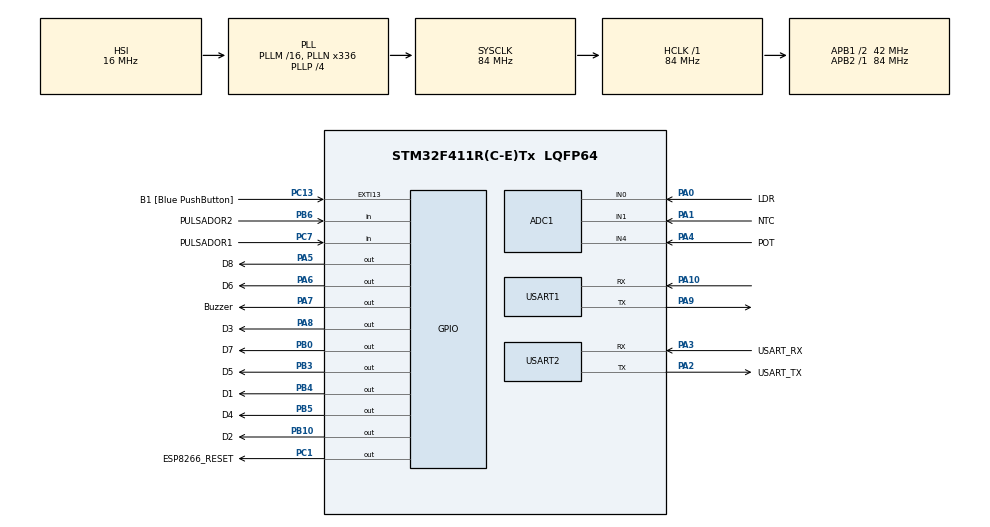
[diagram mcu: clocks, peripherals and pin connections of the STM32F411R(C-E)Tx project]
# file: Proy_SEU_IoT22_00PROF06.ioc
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ADC1.Channel-0\#ChannelRegularConversion=ADC_CHANNEL_0
ADC1.NbrOfConversionFlag=1
ADC1.Rank-0\#ChannelRegularConversion=1
ADC1.SamplingTime-0\#ChannelRegularConversion=ADC_SAMPLETIME_3CYCLES
ADC1.master=1
Dma.Request0=USART1_RX
Dma.Request1=USART2_RX
Dma.Request2=USART1_TX
Dma.USART1_RX.0.Direction=DMA_PERIPH_TO_MEMORY
Dma.USART1_RX.0.FIFOMode=DMA_FIFOMODE_DISABLE
Dma.USART1_RX.0.Instance=DMA2_Stream2
Dma.USART1_RX.0.MemDataAlignment=DMA_MDATAALIGN_BYTE
Dma.USART1_RX.0.MemInc=DMA_MINC_ENABLE
Dma.USART1_RX.0.Mode=DMA_NORMAL
Dma.USART1_RX.0.PeriphDataAlignment=DMA_PDATAALIGN_BYTE
Dma.USART1_RX.0.PeriphInc=DMA_PINC_DISABLE
Dma.USART1_RX.0.Priority=DMA_PRIORITY_LOW
Dma.USART1_TX.2.Direction=DMA_MEMORY_TO_PERIPH
Dma.USART1_TX.2.FIFOMode=DMA_FIFOMODE_DISABLE
Dma.USART1_TX.2.Instance=DMA2_Stream7
Dma.USART1_TX.2.MemDataAlignment=DMA_MDATAALIGN_BYTE
Dma.USART1_TX.2.MemInc=DMA_MINC_ENABLE
Dma.USART1_TX.2.Mode=DMA_NORMAL
Dma.USART1_TX.2.PeriphDataAlignment=DMA_PDATAALIGN_BYTE
Dma.USART1_TX.2.PeriphInc=DMA_PINC_DISABLE
Dma.USART1_TX.2.Priority=DMA_PRIORITY_LOW
Dma.USART2_RX.1.Direction=DMA_PERIPH_TO_MEMORY
Dma.USART2_RX.1.FIFOMode=DMA_FIFOMODE_DISABLE
Dma.USART2_RX.1.Instance=DMA1_Stream5
Dma.USART2_RX.1.MemDataAlignment=DMA_MDATAALIGN_BYTE
Dma.USART2_RX.1.MemInc=DMA_MINC_ENABLE
Dma.USART2_RX.1.Mode=DMA_NORMAL
Dma.USART2_RX.1.PeriphDataAlignment=DMA_PDATAALIGN_BYTE
Dma.USART2_RX.1.PeriphInc=DMA_PINC_DISABLE
Dma.USART2_RX.1.Priority=DMA_PRIORITY_LOW
FREERTOS.INCLUDE_vTaskDelayUntil=1
FREERTOS.Tasks01=defaultTask,24,128,StartDefaultTask,Default,NULL,Dynamic,NULL,NULL
FREERTOS.configENABLE_FPU=1
FREERTOS.configTOTAL_HEAP_SIZE=80000
FREERTOS.configUSE_NEWLIB_REENTRANT=1
Mcu.Family=STM32F4
Mcu.Name=STM32F411R(C-E)Tx
Mcu.Package=LQFP64
NVIC.DMA1_Stream5_IRQn=true\:5\:0\:false\:false\:true\:true\:true\:true\:true
NVIC.DMA2_Stream2_IRQn=true\:5\:0\:false\:false\:true\:true\:true\:true\:true
NVIC.DMA2_Stream7_IRQn=true\:5\:0\:false\:false\:true\:true\:true\:true\:true
NVIC.PriorityGroup=NVIC_PRIORITYGROUP_4
PA0-WKUP.GPIO_Label=LDR
PA0-WKUP.Signal=ADCx_IN0
PA1.GPIO_Label=NTC
PA1.Signal=ADCx_IN1
PA10.Mode=Asynchronous
PA10.Signal=USART1_RX
PA13.GPIO_Label=TMS
PA13.Mode=Serial_Wire
PA13.Signal=SYS_JTMS-SWDIO
PA14.GPIO_Label=TCK
PA14.Mode=Serial_Wire
PA14.Signal=SYS_JTCK-SWCLK
PA2.GPIO_Label=USART_TX
PA2.Mode=Asynchronous
PA2.Signal=USART2_TX
PA3.GPIO_Label=USART_RX
PA3.Mode=Asynchronous
PA3.Signal=USART2_RX
PA4.GPIO_Label=POT
PA4.Signal=ADCx_IN4
PA5.GPIO_Label=D8
PA5.Signal=GPIO_Output
PA6.GPIO_Label=D6
PA6.GPIO_Speed=GPIO_SPEED_FREQ_HIGH
PA6.PinState=GPIO_PIN_SET
PA6.Signal=GPIO_Output
PA7.GPIO_Label=Buzzer
PA7.Signal=GPIO_Output
PA8.GPIO_Label=D3
PA8.Signal=GPIO_Output
PA9.Mode=Asynchronous
PA9.Signal=USART1_TX
PB0.GPIO_Label=D7
PB0.Signal=GPIO_Output
PB10.GPIO_Label=D2
PB10.Signal=GPIO_Output
PB3.GPIO_Label=D5
PB3.Signal=GPIO_Output
PB4.GPIO_Label=D1
PB4.Signal=GPIO_Output
PB5.GPIO_Label=D4
PB5.Signal=GPIO_Output
PB6.GPIO_Label=PULSADOR2
PB6.GPIO_PuPd=GPIO_PULLUP
PB6.Signal=GPIO_Input
PC1.GPIO_Label=ESP8266_RESET
PC1.PinState=GPIO_PIN_RESET
PC1.Signal=GPIO_Output
PC13-ANTI_TAMP.GPIO_Label=B1 [Blue PushButton]
PC13-ANTI_TAMP.GPIO_ModeDefaultEXTI=GPIO_MODE_IT_FALLING
PC13-ANTI_TAMP.Signal=GPXTI13
PC14-OSC32_IN.Mode=LSE-External-Oscillator
PC14-OSC32_IN.Signal=RCC_OSC32_IN
PC15-OSC32_OUT.Mode=LSE-External-Oscillator
PC15-OSC32_OUT.Signal=RCC_OSC32_OUT
PC7.GPIO_Label=PULSADOR1
PC7.GPIO_PuPd=GPIO_PULLUP
PC7.Signal=GPIO_Input
PH0\ -\ OSC_IN.Mode=HSE-External-Clock-Source
PH0\ -\ OSC_IN.Signal=RCC_OSC_IN
PH1\ -\ OSC_OUT.Mode=HSE-External-Clock-Source
PH1\ -\ OSC_OUT.Signal=RCC_OSC_OUT
ProjectManager.HeapSize=0x200
ProjectManager.StackSize=0x400
ProjectManager.TargetToolchain=STM32CubeIDE
RCC.48MHZClocksFreq_Value=84000000
RCC.AHBFreq_Value=84000000
RCC.APB1CLKDivider=RCC_HCLK_DIV2
RCC.APB1Freq_Value=42000000
RCC.APB1TimFreq_Value=84000000
RCC.APB2Freq_Value=84000000
RCC.APB2TimFreq_Value=84000000
RCC.CortexFreq_Value=84000000
RCC.FLatency-AdvancedSettings=FLASH_LATENCY_2
RCC.HCLKFreq_Value=84000000
RCC.HSE_VALUE=8000000
RCC.HSI_VALUE=16000000
RCC.PLLN=336
RCC.PLLP=RCC_PLLP_DIV4
RCC.SYSCLKFreq_VALUE=84000000
RCC.SYSCLKSource=RCC_SYSCLKSOURCE_PLLCLK
RCC.VCOOutputFreq_Value=336000000
SH.ADCx_IN0.0=ADC1_IN0,IN0
SH.ADCx_IN1.0=ADC1_IN1,IN1
SH.ADCx_IN4.0=ADC1_IN4,IN4
USART1.VirtualMode=VM_ASYNC
USART2.VirtualMode=VM_ASYNC
VP_FREERTOS_VS_CMSIS_V2.Mode=CMSIS_V2
board=NUCLEO-F411RE

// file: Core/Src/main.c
/* USER CODE BEGIN Header */
/**
  ******************************************************************************
  * @file           : main.c
  * @brief          : Main program body
  ******************************************************************************
  * @attention
  *
  * <h2><center>&copy; Copyright (c) 2021 STMicroelectronics.
  * All rights reserved.</center></h2>
  *
  * This software component is licensed by ST under BSD 3-Clause license,
  * the "License"; You may not use this file except in compliance with the
  * License. You may obtain a copy of the License at:
  *                        opensource.org/licenses/BSD-3-Clause
  *
  ******************************************************************************
  */
/* USER CODE END Header */
#include "main.h"
#include "cmsis_os.h"

/* USER CODE BEGIN Includes */
#include "tareas.h"

/* USER CODE END Includes */

 ADC_HandleTypeDef hadc1;

UART_HandleTypeDef huart1;
UART_HandleTypeDef huart2;
DMA_HandleTypeDef hdma_usart1_rx;
DMA_HandleTypeDef hdma_usart1_tx;
DMA_HandleTypeDef hdma_usart2_rx;

/* Definitions for defaultTask */
osThreadId_t defaultTaskHandle;
const osThreadAttr_t defaultTask_attributes = {
  .name = "defaultTask",
  .stack_size = 128 * 4,
  .priority = (osPriority_t) osPriorityNormal,
};
/* USER CODE BEGIN PV */
DMA_HandleTypeDef hdma_usart2_rx2;
/* USER CODE END PV */

void SystemClock_Config(void);
static void MX_GPIO_Init(void);
static void MX_DMA_Init(void);
static void MX_USART2_UART_Init(void);
static void MX_USART1_UART_Init(void);
static void MX_ADC1_Init(void);
void StartDefaultTask(void *argument);

int main(void)
{

  /* MCU Configuration--------------------------------------------------------*/

  /* Reset of all peripherals, Initializes the Flash interface and the Systick. */
  HAL_Init();

  /* Configure the system clock */
  SystemClock_Config();

  /* Initialize all configured peripherals */
  MX_GPIO_Init();
  MX_DMA_Init();
  MX_USART2_UART_Init();
  MX_USART1_UART_Init();
  MX_ADC1_Init();

  /* Init scheduler */
  osKernelInitialize();

  /* Create the thread(s) */
  /* creation of defaultTask */
  defaultTaskHandle = osThreadNew(StartDefaultTask, NULL, &defaultTask_attributes);

  /* USER CODE BEGIN RTOS_THREADS */
  /* add threads, ... */
  ESP8266_CONFIGURACION_INICIAL();

  // seminario_sincronizacion();
  /* USER CODE END RTOS_THREADS */

  /* Start scheduler */
  osKernelStart();

  /* We should never get here as control is now taken by the scheduler */
  /* Infinite loop */
  while (1)
  {

  }
}

void SystemClock_Config(void)
{
  RCC_OscInitTypeDef RCC_OscInitStruct = {0};
  RCC_ClkInitTypeDef RCC_ClkInitStruct = {0};

  /** Configure the main internal regulator output voltage
  */
  __HAL_RCC_PWR_CLK_ENABLE();
  __HAL_PWR_VOLTAGESCALING_CONFIG(PWR_REGULATOR_VOLTAGE_SCALE1);

  /** Initializes the RCC Oscillators according to the specified parameters
  * in the RCC_OscInitTypeDef structure.
  */
  RCC_OscInitStruct.OscillatorType = RCC_OSCILLATORTYPE_HSI;
  RCC_OscInitStruct.HSIState = RCC_HSI_ON;
  RCC_OscInitStruct.HSICalibrationValue = RCC_HSICALIBRATION_DEFAULT;
  RCC_OscInitStruct.PLL.PLLState = RCC_PLL_ON;
  RCC_OscInitStruct.PLL.PLLSource = RCC_PLLSOURCE_HSI;
  RCC_OscInitStruct.PLL.PLLM = 16;
  RCC_OscInitStruct.PLL.PLLN = 336;
  RCC_OscInitStruct.PLL.PLLP = RCC_PLLP_DIV4;
  RCC_OscInitStruct.PLL.PLLQ = 4;
  if (HAL_RCC_OscConfig(&RCC_OscInitStruct) != HAL_OK)
  {
    Error_Handler();
  }

  /** Initializes the CPU, AHB and APB buses clocks
  */
  RCC_ClkInitStruct.ClockType = RCC_CLOCKTYPE_HCLK|RCC_CLOCKTYPE_SYSCLK
                              |RCC_CLOCKTYPE_PCLK1|RCC_CLOCKTYPE_PCLK2;
  RCC_ClkInitStruct.SYSCLKSource = RCC_SYSCLKSOURCE_PLLCLK;
  RCC_ClkInitStruct.AHBCLKDivider = RCC_SYSCLK_DIV1;
  RCC_ClkInitStruct.APB1CLKDivider = RCC_HCLK_DIV2;
  RCC_ClkInitStruct.APB2CLKDivider = RCC_HCLK_DIV1;

  if (HAL_RCC_ClockConfig(&RCC_ClkInitStruct, FLASH_LATENCY_2) != HAL_OK)
  {
    Error_Handler();
  }
}

static void MX_ADC1_Init(void)
{

  ADC_ChannelConfTypeDef sConfig = {0};

  /** Configure the global features of the ADC (Clock, Resolution, Data Alignment and number of conversion)
  */
  hadc1.Instance = ADC1;
  hadc1.Init.ClockPrescaler = ADC_CLOCK_SYNC_PCLK_DIV4;
  hadc1.Init.Resolution = ADC_RESOLUTION_12B;
  hadc1.Init.ScanConvMode = DISABLE;
  hadc1.Init.ContinuousConvMode = DISABLE;
  hadc1.Init.DiscontinuousConvMode = DISABLE;
  hadc1.Init.ExternalTrigConvEdge = ADC_EXTERNALTRIGCONVEDGE_NONE;
  hadc1.Init.ExternalTrigConv = ADC_SOFTWARE_START;
  hadc1.Init.DataAlign = ADC_DATAALIGN_RIGHT;
  hadc1.Init.NbrOfConversion = 1;
  hadc1.Init.DMAContinuousRequests = DISABLE;
  hadc1.Init.EOCSelection = ADC_EOC_SINGLE_CONV;
  if (HAL_ADC_Init(&hadc1) != HAL_OK)
  {
    Error_Handler();
  }

  /** Configure for the selected ADC regular channel its corresponding rank in the sequencer and its sample time.
  */
  sConfig.Channel = ADC_CHANNEL_0;
  sConfig.Rank = 1;
  sConfig.SamplingTime = ADC_SAMPLETIME_3CYCLES;
  if (HAL_ADC_ConfigChannel(&hadc1, &sConfig) != HAL_OK)
  {
    Error_Handler();
  }

}

static void MX_USART1_UART_Init(void)
{

  huart1.Instance = USART1;
  huart1.Init.BaudRate = 115200;
  huart1.Init.WordLength = UART_WORDLENGTH_8B;
  huart1.Init.StopBits = UART_STOPBITS_1;
  huart1.Init.Parity = UART_PARITY_NONE;
  huart1.Init.Mode = UART_MODE_TX_RX;
  huart1.Init.HwFlowCtl = UART_HWCONTROL_NONE;
  huart1.Init.OverSampling = UART_OVERSAMPLING_16;
  if (HAL_UART_Init(&huart1) != HAL_OK)
  {
    Error_Handler();
  }

}

static void MX_USART2_UART_Init(void)
{

  huart2.Instance = USART2;
  huart2.Init.BaudRate = 115200;
  huart2.Init.WordLength = UART_WORDLENGTH_8B;
  huart2.Init.StopBits = UART_STOPBITS_1;
  huart2.Init.Parity = UART_PARITY_NONE;
  huart2.Init.Mode = UART_MODE_TX_RX;
  huart2.Init.HwFlowCtl = UART_HWCONTROL_NONE;
  huart2.Init.OverSampling = UART_OVERSAMPLING_16;
  if (HAL_UART_Init(&huart2) != HAL_OK)
  {
    Error_Handler();
  }

}

static void MX_DMA_Init(void)
{

  /* DMA controller clock enable */
  __HAL_RCC_DMA2_CLK_ENABLE();
  __HAL_RCC_DMA1_CLK_ENABLE();

  /* DMA interrupt init */
  /* DMA1_Stream5_IRQn interrupt configuration */
  HAL_NVIC_SetPriority(DMA1_Stream5_IRQn, 5, 0);
  HAL_NVIC_EnableIRQ(DMA1_Stream5_IRQn);
  /* DMA2_Stream2_IRQn interrupt configuration */
  HAL_NVIC_SetPriority(DMA2_Stream2_IRQn, 5, 0);
  HAL_NVIC_EnableIRQ(DMA2_Stream2_IRQn);
  /* DMA2_Stream7_IRQn interrupt configuration */
  HAL_NVIC_SetPriority(DMA2_Stream7_IRQn, 5, 0);
  HAL_NVIC_EnableIRQ(DMA2_Stream7_IRQn);

}

static void MX_GPIO_Init(void)
{
  GPIO_InitTypeDef GPIO_InitStruct = {0};

  /* GPIO Ports Clock Enable */
  __HAL_RCC_GPIOC_CLK_ENABLE();
  __HAL_RCC_GPIOH_CLK_ENABLE();
  __HAL_RCC_GPIOA_CLK_ENABLE();
  __HAL_RCC_GPIOB_CLK_ENABLE();

  /*Configure GPIO pin Output Level */
  HAL_GPIO_WritePin(ESP8266_RESET_GPIO_Port, ESP8266_RESET_Pin, GPIO_PIN_RESET);

  /*Configure GPIO pin Output Level */
  HAL_GPIO_WritePin(GPIOA, D8_Pin|Buzzer_Pin|D3_Pin, GPIO_PIN_RESET);

  /*Configure GPIO pin Output Level */
  HAL_GPIO_WritePin(D6_GPIO_Port, D6_Pin, GPIO_PIN_SET);

  /*Configure GPIO pin Output Level */
  HAL_GPIO_WritePin(GPIOB, D7_Pin|D2_Pin|D5_Pin|D1_Pin
                          |D4_Pin, GPIO_PIN_RESET);

  /*Configure GPIO pin : B1_Pin */
  GPIO_InitStruct.Pin = B1_Pin;
  GPIO_InitStruct.Mode = GPIO_MODE_IT_FALLING;
  GPIO_InitStruct.Pull = GPIO_NOPULL;
  HAL_GPIO_Init(B1_GPIO_Port, &GPIO_InitStruct);

  /*Configure GPIO pin : ESP8266_RESET_Pin */
  GPIO_InitStruct.Pin = ESP8266_RESET_Pin;
  GPIO_InitStruct.Mode = GPIO_MODE_OUTPUT_PP;
  GPIO_InitStruct.Pull = GPIO_NOPULL;
  GPIO_InitStruct.Speed = GPIO_SPEED_FREQ_LOW;
  HAL_GPIO_Init(ESP8266_RESET_GPIO_Port, &GPIO_InitStruct);

  /*Configure GPIO pins : D8_Pin Buzzer_Pin D3_Pin */
  GPIO_InitStruct.Pin = D8_Pin|Buzzer_Pin|D3_Pin;
  GPIO_InitStruct.Mode = GPIO_MODE_OUTPUT_PP;
  GPIO_InitStruct.Pull = GPIO_NOPULL;
  GPIO_InitStruct.Speed = GPIO_SPEED_FREQ_LOW;
  HAL_GPIO_Init(GPIOA, &GPIO_InitStruct);

  /*Configure GPIO pin : D6_Pin */
  GPIO_InitStruct.Pin = D6_Pin;
  GPIO_InitStruct.Mode = GPIO_MODE_OUTPUT_PP;
  GPIO_InitStruct.Pull = GPIO_NOPULL;
  GPIO_InitStruct.Speed = GPIO_SPEED_FREQ_HIGH;
  HAL_GPIO_Init(D6_GPIO_Port, &GPIO_InitStruct);

  /*Configure GPIO pins : D7_Pin D2_Pin D5_Pin D1_Pin
                           D4_Pin */
  GPIO_InitStruct.Pin = D7_Pin|D2_Pin|D5_Pin|D1_Pin
                          |D4_Pin;
  GPIO_InitStruct.Mode = GPIO_MODE_OUTPUT_PP;
  GPIO_InitStruct.Pull = GPIO_NOPULL;
  GPIO_InitStruct.Speed = GPIO_SPEED_FREQ_LOW;
  HAL_GPIO_Init(GPIOB, &GPIO_InitStruct);

  /*Configure GPIO pin : PULSADOR1_Pin */
  GPIO_InitStruct.Pin = PULSADOR1_Pin;
  GPIO_InitStruct.Mode = GPIO_MODE_INPUT;
  GPIO_InitStruct.Pull = GPIO_PULLUP;
  HAL_GPIO_Init(PULSADOR1_GPIO_Port, &GPIO_InitStruct);

  /*Configure GPIO pin : PULSADOR2_Pin */
  GPIO_InitStruct.Pin = PULSADOR2_Pin;
  GPIO_InitStruct.Mode = GPIO_MODE_INPUT;
  GPIO_InitStruct.Pull = GPIO_PULLUP;
  HAL_GPIO_Init(PULSADOR2_GPIO_Port, &GPIO_InitStruct);

}

void StartDefaultTask(void *argument)
{
  for(;;)
  {
    osDelay(1);
  }
}

void Error_Handler(void)
{
  __disable_irq();
  while (1)
  {
  }
}
